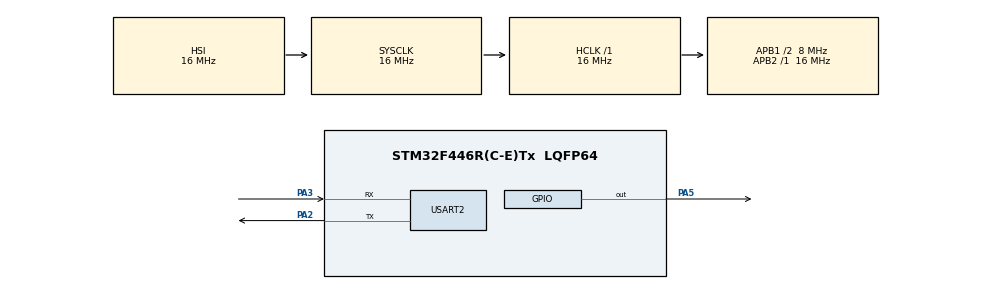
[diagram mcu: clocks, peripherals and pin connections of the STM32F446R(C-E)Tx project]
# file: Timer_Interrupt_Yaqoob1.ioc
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Mcu.Family=STM32F4
Mcu.Name=STM32F446R(C-E)Tx
Mcu.Package=LQFP64
NVIC.PriorityGroup=NVIC_PRIORITYGROUP_0
NVIC.TIM2_IRQn=true\:0\:0\:false\:false\:true\:true\:true
PA2.Mode=Asynchronous
PA2.Signal=USART2_TX
PA3.Mode=Asynchronous
PA3.Signal=USART2_RX
PA5.Signal=GPIO_Output
ProjectManager.HeapSize=0x200
ProjectManager.StackSize=0x400
ProjectManager.TargetToolchain=STM32CubeIDE
RCC.AHBFreq_Value=16000000
RCC.APB1CLKDivider=RCC_HCLK_DIV2
RCC.APB1Freq_Value=8000000
RCC.APB1TimFreq_Value=16000000
RCC.APB2Freq_Value=16000000
RCC.APB2TimFreq_Value=16000000
RCC.CortexFreq_Value=16000000
RCC.FLatency-AdvancedSettings=FLASH_LATENCY_0
RCC.HCLKFreq_Value=16000000
RCC.HSE_VALUE=8000000
RCC.HSI_VALUE=16000000
RCC.LSE_VALUE=32768
RCC.PLLN=336
RCC.PLLP=RCC_PLLP_DIV4
RCC.SYSCLKFreq_VALUE=16000000
RCC.USBFreq_Value=168000000
RCC.VCOOutputFreq_Value=336000000
TIM2.Period=1000
TIM2.Prescaler=16000
TIM2.TIM_MasterOutputTrigger=TIM_TRGO_UPDATE
USART2.VirtualMode=VM_ASYNC
VP_TIM2_VS_ClockSourceINT.Mode=Internal
board=NUCLEO-F446RE

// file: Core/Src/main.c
/* USER CODE BEGIN Header */
/**
  ******************************************************************************
  * @file           : main.c
  * @brief          : Main program body
  ******************************************************************************
  * @attention
  *
  * <h2><center>&copy; Copyright (c) 2020 STMicroelectronics.
  * All rights reserved.</center></h2>
  *
  * This software component is licensed by ST under BSD 3-Clause license,
  * the "License"; You may not use this file except in compliance with the
  * License. You may obtain a copy of the License at:
  *                        opensource.org/licenses/BSD-3-Clause
  *
  ******************************************************************************
  */
/* USER CODE END Header */

#include "main.h"

TIM_HandleTypeDef htim2;

UART_HandleTypeDef huart2;

void SystemClock_Config(void);
static void MX_GPIO_Init(void);
static void MX_TIM2_Init(void);
static void MX_USART2_UART_Init(void);

/* USER CODE BEGIN 0 */
uint32_t counterVal;
char uartData[3000];
/* USER CODE END 0 */

int main(void)
{

  /* MCU Configuration--------------------------------------------------------*/

  /* Reset of all peripherals, Initializes the Flash interface and the Systick. */
  HAL_Init();

  /* Configure the system clock */
  SystemClock_Config();

  /* Initialize all configured peripherals */
  MX_GPIO_Init();
  MX_TIM2_Init();
  MX_USART2_UART_Init();
  /* USER CODE BEGIN 2 */
  HAL_TIM_Base_Start_IT(&htim2);
  HAL_TIM_IC_Start(&htim2,TIM_CHANNEL_1);
  /* USER CODE END 2 */

  /* Infinite loop */
  while (1)
  {

    /* USER CODE BEGIN 3 */
	  counterVal = __HAL_TIM_GetCounter(&htim2);
	  if(counterVal > 990){
		  sprintf(uartData,"time value = %hu\r\n",counterVal);
		  HAL_UART_Transmit(&huart2,uartData,strlen(uartData),10);
	  }
  }
  /* USER CODE END 3 */
}

void SystemClock_Config(void)
{
  RCC_OscInitTypeDef RCC_OscInitStruct = {0};
  RCC_ClkInitTypeDef RCC_ClkInitStruct = {0};

  /** Configure the main internal regulator output voltage
  */
  __HAL_RCC_PWR_CLK_ENABLE();
  __HAL_PWR_VOLTAGESCALING_CONFIG(PWR_REGULATOR_VOLTAGE_SCALE3);
  /** Initializes the CPU, AHB and APB busses clocks
  */
  RCC_OscInitStruct.OscillatorType = RCC_OSCILLATORTYPE_HSI;
  RCC_OscInitStruct.HSIState = RCC_HSI_ON;
  RCC_OscInitStruct.HSICalibrationValue = RCC_HSICALIBRATION_DEFAULT;
  RCC_OscInitStruct.PLL.PLLState = RCC_PLL_NONE;
  if (HAL_RCC_OscConfig(&RCC_OscInitStruct) != HAL_OK)
  {
    Error_Handler();
  }
  /** Initializes the CPU, AHB and APB busses clocks
  */
  RCC_ClkInitStruct.ClockType = RCC_CLOCKTYPE_HCLK|RCC_CLOCKTYPE_SYSCLK
                              |RCC_CLOCKTYPE_PCLK1|RCC_CLOCKTYPE_PCLK2;
  RCC_ClkInitStruct.SYSCLKSource = RCC_SYSCLKSOURCE_HSI;
  RCC_ClkInitStruct.AHBCLKDivider = RCC_SYSCLK_DIV1;
  RCC_ClkInitStruct.APB1CLKDivider = RCC_HCLK_DIV2;
  RCC_ClkInitStruct.APB2CLKDivider = RCC_HCLK_DIV1;

  if (HAL_RCC_ClockConfig(&RCC_ClkInitStruct, FLASH_LATENCY_0) != HAL_OK)
  {
    Error_Handler();
  }
}

static void MX_TIM2_Init(void)
{

  TIM_ClockConfigTypeDef sClockSourceConfig = {0};
  TIM_MasterConfigTypeDef sMasterConfig = {0};

  htim2.Instance = TIM2;
  htim2.Init.Prescaler = 16000;
  htim2.Init.CounterMode = TIM_COUNTERMODE_UP;
  htim2.Init.Period = 1000;
  htim2.Init.ClockDivision = TIM_CLOCKDIVISION_DIV1;
  htim2.Init.AutoReloadPreload = TIM_AUTORELOAD_PRELOAD_DISABLE;
  if (HAL_TIM_Base_Init(&htim2) != HAL_OK)
  {
    Error_Handler();
  }
  sClockSourceConfig.ClockSource = TIM_CLOCKSOURCE_INTERNAL;
  if (HAL_TIM_ConfigClockSource(&htim2, &sClockSourceConfig) != HAL_OK)
  {
    Error_Handler();
  }
  sMasterConfig.MasterOutputTrigger = TIM_TRGO_UPDATE;
  sMasterConfig.MasterSlaveMode = TIM_MASTERSLAVEMODE_DISABLE;
  if (HAL_TIMEx_MasterConfigSynchronization(&htim2, &sMasterConfig) != HAL_OK)
  {
    Error_Handler();
  }

}

static void MX_USART2_UART_Init(void)
{

  huart2.Instance = USART2;
  huart2.Init.BaudRate = 115200;
  huart2.Init.WordLength = UART_WORDLENGTH_8B;
  huart2.Init.StopBits = UART_STOPBITS_1;
  huart2.Init.Parity = UART_PARITY_NONE;
  huart2.Init.Mode = UART_MODE_TX_RX;
  huart2.Init.HwFlowCtl = UART_HWCONTROL_NONE;
  huart2.Init.OverSampling = UART_OVERSAMPLING_16;
  if (HAL_UART_Init(&huart2) != HAL_OK)
  {
    Error_Handler();
  }

}

static void MX_GPIO_Init(void)
{
  GPIO_InitTypeDef GPIO_InitStruct = {0};

  /* GPIO Ports Clock Enable */
  __HAL_RCC_GPIOA_CLK_ENABLE();

  /*Configure GPIO pin Output Level */
  HAL_GPIO_WritePin(GPIOA, GPIO_PIN_5, GPIO_PIN_RESET);

  /*Configure GPIO pin : PA5 */
  GPIO_InitStruct.Pin = GPIO_PIN_5;
  GPIO_InitStruct.Mode = GPIO_MODE_OUTPUT_PP;
  GPIO_InitStruct.Pull = GPIO_NOPULL;
  GPIO_InitStruct.Speed = GPIO_SPEED_FREQ_LOW;
  HAL_GPIO_Init(GPIOA, &GPIO_InitStruct);

}

/* USER CODE BEGIN 4 */
void HAL_TIM_PeriodElapsedCallback(TIM_HandleTypeDef *htim)
{
  /* Prevent unused argument(s) compilation warning */
  UNUSED(htim);

  /* NOTE : This function should not be modified, when the callback is needed,
            the HAL_TIM_PeriodElapsedCallback could be implemented in the user file
   */

  HAL_GPIO_TogglePin(GPIOA,GPIO_PIN_5);
}

/* USER CODE END 4 */

void Error_Handler(void)
{
}

/************************ (C) COPYRIGHT STMicroelectronics *****END OF FILE****/
